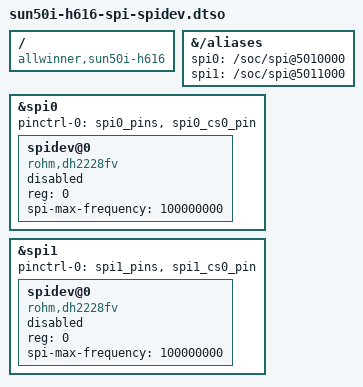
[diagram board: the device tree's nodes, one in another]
/dts-v1/;
/plugin/;

/ {
	compatible = "allwinner,sun50i-h616";

	fragment@0 {
		target-path = "/aliases";
		__overlay__ {
			spi0 = "/soc/spi@5010000";
			spi1 = "/soc/spi@5011000";
		};
	};

	fragment@1 {
		target = <&spi0>;
		__overlay__ {
			status = "okay";
			#address-cells = <1>;
			#size-cells = <0>;
			pinctrl-names = "default";
			pinctrl-0 = <&spi0_pins>, <&spi0_cs0_pin>;

			spidev@0 {
				compatible = "rohm,dh2228fv";
				status = "disabled";
				reg = <0>;
				spi-max-frequency = <100000000>;
			};
		};
	};

	fragment@2 {
		target = <&spi1>;
		__overlay__ {
			status = "okay";
			#address-cells = <1>;
			#size-cells = <0>;
			pinctrl-names = "default";
			pinctrl-0 = <&spi1_pins>, <&spi1_cs0_pin>;

			spidev@0 {
				compatible = "rohm,dh2228fv";
				status = "disabled";
				reg = <0>;
				spi-max-frequency = <100000000>;
			};
		};
	};
};
